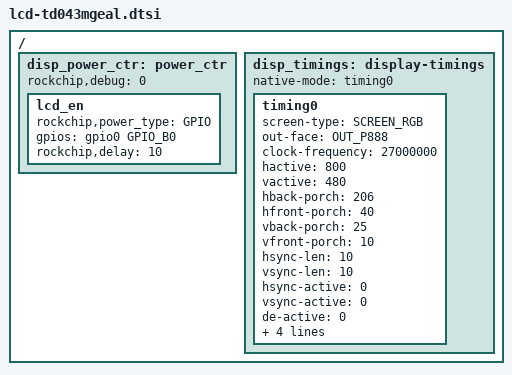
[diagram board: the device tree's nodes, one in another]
/*
 * RockChip. LCD_TD043MGEA1 FOR FPGA
 *
 */

/ {
	 	disp_power_ctr: power_ctr {
                        rockchip,debug = <0>;
                        lcd_en:lcd_en {
                                rockchip,power_type = <GPIO>;
                                gpios = <&gpio0 GPIO_B0 GPIO_ACTIVE_HIGH>;
                                rockchip,delay = <10>;
                        };

                     /*   bl_en:bl_en {
                                rockchip,power_type = <GPIO>;
                                gpios = <&gpio0 GPIO_A2 GPIO_ACTIVE_HIGH>;
                                rockchip,delay = <10>;
                        };

                        bl_ctr:bl_ctr {
                                rockchip,power_type = <GPIO>;
                                gpios = <&gpio3 GPIO_D6 GPIO_ACTIVE_HIGH>;
                                rockchip,delay = <10>;
                        };

                        lcd_rst:lcd_rst {
                                rockchip,power_type = <REGULATOR>;
                                rockchip,delay = <5>;
                        };*/

                };

		disp_timings: display-timings {
                        native-mode = <&timing0>;
                        timing0: timing0 {
				screen-type = <SCREEN_RGB>;
				out-face    = <OUT_P888>;
				clock-frequency = <27000000>;
				hactive = <800>;
				vactive = <480>;
				hback-porch = <206>;
				hfront-porch = <40>;
				vback-porch = <25>;
				vfront-porch = <10>;
				hsync-len = <10>;
				vsync-len = <10>;
				hsync-active = <0>;
				vsync-active = <0>;
				de-active = <0>;
				pixelclk-active = <0>;
				swap-rb = <0>;
				swap-rg = <0>;
				swap-gb = <0>;
                     	};
               };
};
